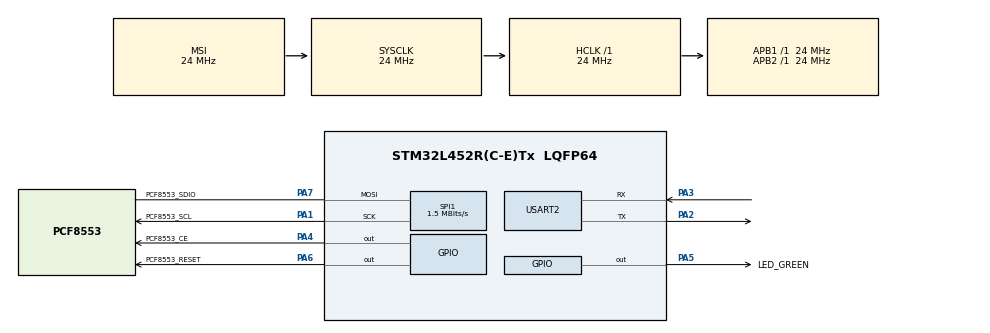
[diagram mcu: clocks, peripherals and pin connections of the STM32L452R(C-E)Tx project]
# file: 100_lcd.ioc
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ADC1.Channel-0\#ChannelRegularConversion=ADC_CHANNEL_TEMPSENSOR
ADC1.ClockPrescaler=ADC_CLOCK_ASYNC_DIV2
ADC1.NbrOfConversionFlag=1
ADC1.OffsetNumber-0\#ChannelRegularConversion=ADC_OFFSET_NONE
ADC1.Rank-0\#ChannelRegularConversion=1
ADC1.SamplingTime-0\#ChannelRegularConversion=ADC_SAMPLETIME_24CYCLES_5
ADC1.master=1
FREERTOS.BinarySemaphores01=counter_semaphore,Dynamic,NULL
FREERTOS.Tasks01=CounterTask,24,256,counter_task,Default,NULL,Dynamic,NULL,NULL
FREERTOS.configUSE_NEWLIB_REENTRANT=1
FREERTOS.configUSE_TICKLESS_IDLE=0
Mcu.Family=STM32L4
Mcu.Name=STM32L452R(C-E)Tx
Mcu.Package=LQFP64
NVIC.PriorityGroup=NVIC_PRIORITYGROUP_4
NVIC.RTC_WKUP_IRQn=true\:5\:0\:false\:false\:true\:true\:true\:true\:true
NVIC.TIM6_DAC_IRQn=true\:15\:0\:false\:false\:true\:false\:false\:true\:true
NVIC.TimeBase=TIM6_DAC_IRQn
NVIC.TimeBaseIP=TIM6
PA1.GPIO_Label=PCF8553_SCL
PA1.GPIO_Mode=GPIO_MODE_AF_PP
PA1.GPIO_PuPd=GPIO_NOPULL
PA1.GPIO_Speed=GPIO_SPEED_FREQ_VERY_HIGH
PA1.Mode=Simplex_Bidirectional_Master
PA1.Signal=SPI1_SCK
PA13\ (JTMS/SWDIO).Mode=Trace_Asynchronous_SW
PA13\ (JTMS/SWDIO).Signal=SYS_JTMS-SWDIO
PA14\ (JTCK/SWCLK).Mode=Trace_Asynchronous_SW
PA14\ (JTCK/SWCLK).Signal=SYS_JTCK-SWCLK
PA2.Mode=Asynchronous
PA2.Signal=USART2_TX
PA3.Mode=Asynchronous
PA3.Signal=USART2_RX
PA4.GPIO_Label=PCF8553_CE
PA4.Signal=GPIO_Output
PA5.GPIO_Label=LED_GREEN
PA5.Signal=GPIO_Output
PA6.GPIO_Label=PCF8553_RESET
PA6.Signal=GPIO_Output
PA7.GPIO_Label=PCF8553_SDIO
PA7.GPIO_Mode=GPIO_MODE_AF_PP
PA7.GPIO_PuPd=GPIO_NOPULL
PA7.GPIO_Speed=GPIO_SPEED_FREQ_VERY_HIGH
PA7.Mode=Simplex_Bidirectional_Master
PA7.Signal=SPI1_MOSI
PB3\ (JTDO/TRACESWO).Mode=Trace_Asynchronous_SW
PB3\ (JTDO/TRACESWO).Signal=SYS_JTDO-SWO
PC14-OSC32_IN\ (PC14).Mode=LSE-External-Oscillator
PC14-OSC32_IN\ (PC14).Signal=RCC_OSC32_IN
PC15-OSC32_OUT\ (PC15).Mode=LSE-External-Oscillator
PC15-OSC32_OUT\ (PC15).Signal=RCC_OSC32_OUT
ProjectManager.HeapSize=0x200
ProjectManager.StackSize=0x400
ProjectManager.TargetToolchain=STM32CubeIDE
RCC.ADCCLockSelection=RCC_ADCCLKSOURCE_SYSCLK
RCC.ADCFreq_Value=24000000
RCC.AHBFreq_Value=24000000
RCC.APB1Freq_Value=24000000
RCC.APB1TimFreq_Value=24000000
RCC.APB2Freq_Value=24000000
RCC.APB2TimFreq_Value=24000000
RCC.CortexFreq_Value=24000000
RCC.HCLKFreq_Value=24000000
RCC.HSE_VALUE=8000000
RCC.HSI48_VALUE=48000000
RCC.HSI_VALUE=16000000
RCC.MSIClockRange=RCC_MSIRANGE_9
RCC.MSI_VALUE=24000000
RCC.PWR_Regulator_Voltage_Scale=PWR_REGULATOR_VOLTAGE_SCALE2
RCC.RTCClockSelection=RCC_RTCCLKSOURCE_LSE
RCC.SYSCLKFreq_VALUE=24000000
RCC.USBFreq_Value=96000000
RCC.VCOOutputFreq_Value=192000000
RTC.WakeUpClock-WakeUp=RTC_WAKEUPCLOCK_RTCCLK_DIV16
RTC.WakeUpCounter-WakeUp=2048
SPI1.BaudRatePrescaler=SPI_BAUDRATEPRESCALER_16
SPI1.CalculateBaudRate=1.5 MBits/s
SPI1.DataSize=SPI_DATASIZE_8BIT
SPI1.Direction=SPI_DIRECTION_1LINE
SPI1.Mode=SPI_MODE_MASTER
SPI1.NSSPMode=SPI_NSS_PULSE_DISABLE
SPI1.VirtualType=VM_MASTER
TIM16.Prescaler=24-1
USART2.VirtualMode-Asynchronous=VM_ASYNC
VP_ADC1_TempSens_Input.Mode=IN-TempSens
VP_ADC1_Vref_Input.Mode=IN-Vrefint
VP_FREERTOS_VS_CMSIS_V2.Mode=CMSIS_V2
VP_RTC_VS_RTC_Activate.Mode=RTC_Enabled
VP_RTC_VS_RTC_WakeUp_intern.Mode=WakeUp
VP_SYS_VS_tim6.Mode=TIM6
VP_TIM16_VS_ClockSourceINT.Mode=Enable_Timer
board=custom

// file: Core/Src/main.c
/* USER CODE BEGIN Header */
/*
 * @brief Este proyecto sirve pare testear el modulo de LCD sin bajo consumo
 *  Se implementa un contador cada 1 segundo. El retardo es con el RTC, se
 *  bloque con un semaforo en la tarea y se lo libera un segundo despues
 *  en la interrupción del RTC.
 *  A medida de que se agreguen mas fuciones se deberia tener un programa
 *  de testeo mas completo.
 *
 */
/* USER CODE END Header */
#include "main.h"
#include "cmsis_os.h"

/* USER CODE BEGIN Includes */
#include "../../../libs/fm_lcd/fm_lcd.h"
//#include "../../../libs/fm_debug/fm_debug.h"

/* USER CODE END Includes */

ADC_HandleTypeDef hadc1;

RTC_HandleTypeDef hrtc;

SPI_HandleTypeDef hspi1;

TIM_HandleTypeDef htim16;

UART_HandleTypeDef huart2;

/* Definitions for CounterTask */
osThreadId_t CounterTaskHandle;
const osThreadAttr_t CounterTask_attributes = {
  .name = "CounterTask",
  .stack_size = 256 * 4,
  .priority = (osPriority_t) osPriorityNormal,
};
/* Definitions for counter_semaphore */
osSemaphoreId_t counter_semaphoreHandle;
const osSemaphoreAttr_t counter_semaphore_attributes = {
  .name = "counter_semaphore"
};

void SystemClock_Config(void);
static void MX_GPIO_Init(void);
static void MX_SPI1_Init(void);
static void MX_RTC_Init(void);
static void MX_TIM16_Init(void);
static void MX_USART2_UART_Init(void);
static void MX_ADC1_Init(void);
void counter_task(void *argument);

int main(void)
{

  /* MCU Configuration--------------------------------------------------------*/

  /* Reset of all peripherals, Initializes the Flash interface and the Systick. */
  HAL_Init();

  /* Configure the system clock */
  SystemClock_Config();

  /* Initialize all configured peripherals */
  MX_GPIO_Init();
  MX_SPI1_Init();
  MX_RTC_Init();
  MX_TIM16_Init();
  MX_USART2_UART_Init();
  MX_ADC1_Init();
  /* USER CODE BEGIN 2 */
    fm_lcd_init();
    fm_lcd_clear();
  /* USER CODE END 2 */

  /* Init scheduler */
  osKernelInitialize();

  /* Create the semaphores(s) */
  /* creation of counter_semaphore */
  counter_semaphoreHandle = osSemaphoreNew(1, 1, &counter_semaphore_attributes);

  /* Create the thread(s) */
  /* creation of CounterTask */
  CounterTaskHandle = osThreadNew(counter_task, NULL, &CounterTask_attributes);

  /* Start scheduler */
  osKernelStart();
  /* We should never get here as control is now taken by the scheduler */
  /* Infinite loop */
    while (1)
    {

    }
}

void SystemClock_Config(void)
{
  RCC_OscInitTypeDef RCC_OscInitStruct = {0};
  RCC_ClkInitTypeDef RCC_ClkInitStruct = {0};

  /** Configure the main internal regulator output voltage
  */
  if (HAL_PWREx_ControlVoltageScaling(PWR_REGULATOR_VOLTAGE_SCALE2) != HAL_OK)
  {
    Error_Handler();
  }

  /** Configure LSE Drive Capability
  */
  HAL_PWR_EnableBkUpAccess();
  __HAL_RCC_LSEDRIVE_CONFIG(RCC_LSEDRIVE_LOW);

  /** Initializes the RCC Oscillators according to the specified parameters
  * in the RCC_OscInitTypeDef structure.
  */
  RCC_OscInitStruct.OscillatorType = RCC_OSCILLATORTYPE_LSE|RCC_OSCILLATORTYPE_MSI;
  RCC_OscInitStruct.LSEState = RCC_LSE_ON;
  RCC_OscInitStruct.MSIState = RCC_MSI_ON;
  RCC_OscInitStruct.MSICalibrationValue = 0;
  RCC_OscInitStruct.MSIClockRange = RCC_MSIRANGE_9;
  RCC_OscInitStruct.PLL.PLLState = RCC_PLL_NONE;
  if (HAL_RCC_OscConfig(&RCC_OscInitStruct) != HAL_OK)
  {
    Error_Handler();
  }

  /** Initializes the CPU, AHB and APB buses clocks
  */
  RCC_ClkInitStruct.ClockType = RCC_CLOCKTYPE_HCLK|RCC_CLOCKTYPE_SYSCLK
                              |RCC_CLOCKTYPE_PCLK1|RCC_CLOCKTYPE_PCLK2;
  RCC_ClkInitStruct.SYSCLKSource = RCC_SYSCLKSOURCE_MSI;
  RCC_ClkInitStruct.AHBCLKDivider = RCC_SYSCLK_DIV1;
  RCC_ClkInitStruct.APB1CLKDivider = RCC_HCLK_DIV1;
  RCC_ClkInitStruct.APB2CLKDivider = RCC_HCLK_DIV1;

  if (HAL_RCC_ClockConfig(&RCC_ClkInitStruct, FLASH_LATENCY_4) != HAL_OK)
  {
    Error_Handler();
  }

  /** Enable MSI Auto calibration
  */
  HAL_RCCEx_EnableMSIPLLMode();
}

static void MX_ADC1_Init(void)
{

  ADC_ChannelConfTypeDef sConfig = {0};

  /** Common config
  */
  hadc1.Instance = ADC1;
  hadc1.Init.ClockPrescaler = ADC_CLOCK_ASYNC_DIV2;
  hadc1.Init.Resolution = ADC_RESOLUTION_12B;
  hadc1.Init.DataAlign = ADC_DATAALIGN_RIGHT;
  hadc1.Init.ScanConvMode = ADC_SCAN_DISABLE;
  hadc1.Init.EOCSelection = ADC_EOC_SINGLE_CONV;
  hadc1.Init.LowPowerAutoWait = DISABLE;
  hadc1.Init.ContinuousConvMode = DISABLE;
  hadc1.Init.NbrOfConversion = 1;
  hadc1.Init.DiscontinuousConvMode = DISABLE;
  hadc1.Init.ExternalTrigConv = ADC_SOFTWARE_START;
  hadc1.Init.ExternalTrigConvEdge = ADC_EXTERNALTRIGCONVEDGE_NONE;
  hadc1.Init.DMAContinuousRequests = DISABLE;
  hadc1.Init.Overrun = ADC_OVR_DATA_PRESERVED;
  hadc1.Init.OversamplingMode = DISABLE;
  hadc1.Init.DFSDMConfig = ADC_DFSDM_MODE_ENABLE;
  if (HAL_ADC_Init(&hadc1) != HAL_OK)
  {
    Error_Handler();
  }

  /** Configure Regular Channel
  */
  sConfig.Channel = ADC_CHANNEL_TEMPSENSOR;
  sConfig.Rank = ADC_REGULAR_RANK_1;
  sConfig.SamplingTime = ADC_SAMPLETIME_24CYCLES_5;
  sConfig.SingleDiff = ADC_SINGLE_ENDED;
  sConfig.OffsetNumber = ADC_OFFSET_NONE;
  sConfig.Offset = 0;
  if (HAL_ADC_ConfigChannel(&hadc1, &sConfig) != HAL_OK)
  {
    Error_Handler();
  }

}

static void MX_RTC_Init(void)
{

  /** Initialize RTC Only
  */
  hrtc.Instance = RTC;
  hrtc.Init.HourFormat = RTC_HOURFORMAT_24;
  hrtc.Init.AsynchPrediv = 127;
  hrtc.Init.SynchPrediv = 255;
  hrtc.Init.OutPut = RTC_OUTPUT_DISABLE;
  hrtc.Init.OutPutRemap = RTC_OUTPUT_REMAP_NONE;
  hrtc.Init.OutPutPolarity = RTC_OUTPUT_POLARITY_HIGH;
  hrtc.Init.OutPutType = RTC_OUTPUT_TYPE_OPENDRAIN;
  if (HAL_RTC_Init(&hrtc) != HAL_OK)
  {
    Error_Handler();
  }

  /** Enable the WakeUp
  */
  if (HAL_RTCEx_SetWakeUpTimer_IT(&hrtc, 2048, RTC_WAKEUPCLOCK_RTCCLK_DIV16) != HAL_OK)
  {
    Error_Handler();
  }

}

static void MX_SPI1_Init(void)
{

  /* SPI1 parameter configuration*/
  hspi1.Instance = SPI1;
  hspi1.Init.Mode = SPI_MODE_MASTER;
  hspi1.Init.Direction = SPI_DIRECTION_1LINE;
  hspi1.Init.DataSize = SPI_DATASIZE_8BIT;
  hspi1.Init.CLKPolarity = SPI_POLARITY_LOW;
  hspi1.Init.CLKPhase = SPI_PHASE_1EDGE;
  hspi1.Init.NSS = SPI_NSS_SOFT;
  hspi1.Init.BaudRatePrescaler = SPI_BAUDRATEPRESCALER_16;
  hspi1.Init.FirstBit = SPI_FIRSTBIT_MSB;
  hspi1.Init.TIMode = SPI_TIMODE_DISABLE;
  hspi1.Init.CRCCalculation = SPI_CRCCALCULATION_DISABLE;
  hspi1.Init.CRCPolynomial = 7;
  hspi1.Init.CRCLength = SPI_CRC_LENGTH_DATASIZE;
  hspi1.Init.NSSPMode = SPI_NSS_PULSE_DISABLE;
  if (HAL_SPI_Init(&hspi1) != HAL_OK)
  {
    Error_Handler();
  }

}

static void MX_TIM16_Init(void)
{

  htim16.Instance = TIM16;
  htim16.Init.Prescaler = 24-1;
  htim16.Init.CounterMode = TIM_COUNTERMODE_UP;
  htim16.Init.Period = 65535;
  htim16.Init.ClockDivision = TIM_CLOCKDIVISION_DIV1;
  htim16.Init.RepetitionCounter = 0;
  htim16.Init.AutoReloadPreload = TIM_AUTORELOAD_PRELOAD_DISABLE;
  if (HAL_TIM_Base_Init(&htim16) != HAL_OK)
  {
    Error_Handler();
  }

}

static void MX_USART2_UART_Init(void)
{

  huart2.Instance = USART2;
  huart2.Init.BaudRate = 115200;
  huart2.Init.WordLength = UART_WORDLENGTH_8B;
  huart2.Init.StopBits = UART_STOPBITS_1;
  huart2.Init.Parity = UART_PARITY_NONE;
  huart2.Init.Mode = UART_MODE_TX_RX;
  huart2.Init.HwFlowCtl = UART_HWCONTROL_NONE;
  huart2.Init.OverSampling = UART_OVERSAMPLING_16;
  huart2.Init.OneBitSampling = UART_ONE_BIT_SAMPLE_DISABLE;
  huart2.AdvancedInit.AdvFeatureInit = UART_ADVFEATURE_NO_INIT;
  if (HAL_UART_Init(&huart2) != HAL_OK)
  {
    Error_Handler();
  }

}

static void MX_GPIO_Init(void)
{
  GPIO_InitTypeDef GPIO_InitStruct = {0};

  /* GPIO Ports Clock Enable */
  __HAL_RCC_GPIOC_CLK_ENABLE();
  __HAL_RCC_GPIOA_CLK_ENABLE();
  __HAL_RCC_GPIOB_CLK_ENABLE();

  /*Configure GPIO pin Output Level */
  HAL_GPIO_WritePin(GPIOA, PCF8553_CE_Pin|LED_GREEN_Pin|PCF8553_RESET_Pin, GPIO_PIN_RESET);

  /*Configure GPIO pins : PCF8553_CE_Pin LED_GREEN_Pin PCF8553_RESET_Pin */
  GPIO_InitStruct.Pin = PCF8553_CE_Pin|LED_GREEN_Pin|PCF8553_RESET_Pin;
  GPIO_InitStruct.Mode = GPIO_MODE_OUTPUT_PP;
  GPIO_InitStruct.Pull = GPIO_NOPULL;
  GPIO_InitStruct.Speed = GPIO_SPEED_FREQ_LOW;
  HAL_GPIO_Init(GPIOA, &GPIO_InitStruct);

}

/* USER CODE BEGIN 4 */

void HAL_RTCEx_WakeUpTimerEventCallback(RTC_HandleTypeDef *hrtc)
{
    osSemaphoreRelease(counter_semaphoreHandle);
    HAL_RTCEx_DeactivateWakeUpTimer(hrtc);
}

/* USER CODE END 4 */

void counter_task(void *argument)
{
  /* USER CODE BEGIN 5 */
    uint8_t counter = 0;
    char msg[10];
    /* Infinite loop */
    for (;;)
    {
        snprintf(msg, sizeof(msg), "%08u", counter);
        fm_lcd_puts(msg, 0);
        fm_lcd_refresh();
        HAL_RTCEx_SetWakeUpTimer_IT(&hrtc, 2048, RTC_WAKEUPCLOCK_RTCCLK_DIV16);
        osSemaphoreAcquire(counter_semaphoreHandle,  4000);
        counter++;

    }
  /* USER CODE END 5 */
}

void HAL_TIM_PeriodElapsedCallback(TIM_HandleTypeDef *htim)
{
  if (htim->Instance == TIM6) {
    HAL_IncTick();
  }
}

void Error_Handler(void)
{
    __disable_irq();
    while (1)
    {
    }
}
